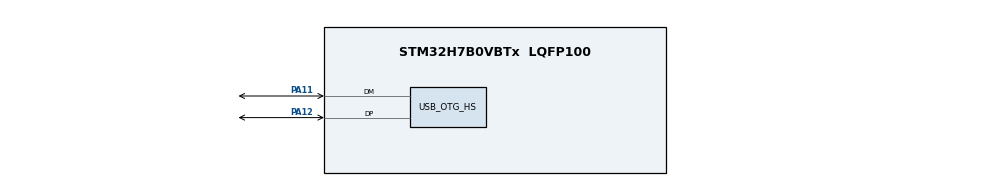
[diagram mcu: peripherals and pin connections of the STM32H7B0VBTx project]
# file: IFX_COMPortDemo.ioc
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Mcu.Family=STM32H7
Mcu.Name=STM32H7B0VBTx
Mcu.Package=LQFP100
NVIC.OTG_HS_EP1_IN_IRQn=true\:0\:0\:false\:false\:true\:true\:true\:true
NVIC.OTG_HS_EP1_OUT_IRQn=true\:0\:0\:false\:false\:true\:true\:true\:true
NVIC.OTG_HS_IRQn=true\:0\:0\:false\:false\:true\:true\:true\:true
NVIC.PriorityGroup=NVIC_PRIORITYGROUP_4
PA11.Mode=Device_Only_FS
PA11.Signal=USB_OTG_HS_DM
PA12.Mode=Device_Only_FS
PA12.Signal=USB_OTG_HS_DP
PA13.Mode=Trace_Asynchronous_SW
PA13.Signal=DEBUG_JTMS-SWDIO
PA14.Mode=Trace_Asynchronous_SW
PA14.Signal=DEBUG_JTCK-SWCLK
PB3.Mode=Trace_Asynchronous_SW
PB3.Signal=DEBUG_JTDO-SWO
PH0-OSC_IN.Mode=HSE-External-Oscillator
PH0-OSC_IN.Signal=RCC_OSC_IN
PH1-OSC_OUT.Mode=HSE-External-Oscillator
PH1-OSC_OUT.Signal=RCC_OSC_OUT
ProjectManager.HeapSize=0x200
ProjectManager.StackSize=0x400
ProjectManager.TargetToolchain=STM32CubeIDE
RCC.ADCFreq_Value=50390625
RCC.APB1Freq_Value=140000000
RCC.APB2Freq_Value=140000000
RCC.APB3Freq_Value=140000000
RCC.APB4Freq_Value=140000000
RCC.CDPPRE=RCC_APB3_DIV2
RCC.CDPPRE1=RCC_APB1_DIV2
RCC.CDPPRE2=RCC_APB2_DIV2
RCC.CortexFreq_Value=280000000
RCC.DIVM1=5
RCC.DIVM3=25
RCC.DIVN1=112
RCC.DIVN3=192
RCC.DIVQ3=4
RCC.HCLKFreq_Value=280000000
RCC.HSE_VALUE=25000000
RCC.PLL2FRACN=0
RCC.PLL3FRACN=0
RCC.PLLFRACN=0
RCC.PLLSourceVirtual=RCC_PLLSOURCE_HSE
RCC.SRDPPRE=RCC_APB4_DIV2
RCC.SYSCLKFreq_VALUE=280000000
RCC.SYSCLKSource=RCC_SYSCLKSOURCE_PLLCLK
RCC.USBCLockSelection=RCC_USBCLKSOURCE_PLL3
RCC.USBFreq_Value=48000000
USB_DEVICE.CLASS_NAME_HS=CDC
USB_DEVICE.VirtualMode=Cdc
USB_DEVICE.VirtualModeHS=Cdc_HS
USB_OTG_HS.VirtualMode-Device_Only_FS=Device_Only_FS
USB_OTG_HS.dma_enable-Device_Only_FS=DISABLE
VP_USB_DEVICE_VS_USB_DEVICE_CDC_HS.Mode=CDC_HS
board=custom

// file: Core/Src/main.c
/* USER CODE BEGIN Header */
/**
  ******************************************************************************
  * @file           : main.c
  * @brief          : Main program body
  ******************************************************************************
  * @attention
  *
  * Copyright (c) 2025 STMicroelectronics.
  * All rights reserved.
  *
  * This software is licensed under terms that can be found in the LICENSE file
  * in the root directory of this software component.
  * If no LICENSE file comes with this software, it is provided AS-IS.
  *
  ******************************************************************************
  */
/* USER CODE END Header */
#include "main.h"
#include "usb_device.h"

/* USER CODE BEGIN Includes */
#include "usbd_cdc_if.h"
/* USER CODE END Includes */

/* USER CODE BEGIN PD */
#define USBBUF_MAXLEN 128
/* USER CODE END PD */

void SystemClock_Config(void);
static void MX_GPIO_Init(void);

/* USER CODE BEGIN 0 */
uint8_t usbTxBuf[USBBUF_MAXLEN];
uint8_t usbRxBuf[USBBUF_MAXLEN];

uint16_t usbTxBufLen = 0;
uint16_t usbRxBufLen = 0;

uint8_t  usbRxFlag 	 = 0;

void USB_RXCallback(uint8_t* Buf, uint32_t *Len) {

	memcpy(usbRxBuf, Buf, *Len);
	usbRxBufLen = *Len;
	usbRxFlag = 1;

}

/* USER CODE END 0 */

int main(void)
{

  /* MCU Configuration--------------------------------------------------------*/

  /* Reset of all peripherals, Initializes the Flash interface and the Systick. */
  HAL_Init();

  /* Configure the system clock */
  SystemClock_Config();

  /* Initialize all configured peripherals */
  MX_GPIO_Init();
  MX_USB_DEVICE_Init();

  /* Infinite loop */
  while (1)
  {

    /* USER CODE BEGIN 3 */
	  if (usbRxFlag && usbRxBufLen) {

		  uint32_t timeNowMS = HAL_GetTick();

		  usbTxBufLen = snprintf((char *) usbTxBuf, USBBUF_MAXLEN, "[%02lu:%02lu] %u\r\n", (timeNowMS / 60000), (timeNowMS / 1000) % 60, usbRxBufLen);

		  CDC_Transmit_HS(usbTxBuf, usbTxBufLen);

		  usbRxFlag = 0;
		  usbRxBufLen = 0;

	  }

  }
  /* USER CODE END 3 */
}

void SystemClock_Config(void)
{
  RCC_OscInitTypeDef RCC_OscInitStruct = {0};
  RCC_ClkInitTypeDef RCC_ClkInitStruct = {0};

  /*AXI clock gating */
  RCC->CKGAENR = 0xFFFFFFFF;

  /** Supply configuration update enable
  */
  HAL_PWREx_ConfigSupply(PWR_LDO_SUPPLY);

  /** Configure the main internal regulator output voltage
  */
  __HAL_PWR_VOLTAGESCALING_CONFIG(PWR_REGULATOR_VOLTAGE_SCALE0);

  while(!__HAL_PWR_GET_FLAG(PWR_FLAG_VOSRDY)) {}

  /** Initializes the RCC Oscillators according to the specified parameters
  * in the RCC_OscInitTypeDef structure.
  */
  RCC_OscInitStruct.OscillatorType = RCC_OSCILLATORTYPE_HSE;
  RCC_OscInitStruct.HSEState = RCC_HSE_ON;
  RCC_OscInitStruct.PLL.PLLState = RCC_PLL_ON;
  RCC_OscInitStruct.PLL.PLLSource = RCC_PLLSOURCE_HSE;
  RCC_OscInitStruct.PLL.PLLM = 5;
  RCC_OscInitStruct.PLL.PLLN = 112;
  RCC_OscInitStruct.PLL.PLLP = 2;
  RCC_OscInitStruct.PLL.PLLQ = 2;
  RCC_OscInitStruct.PLL.PLLR = 2;
  RCC_OscInitStruct.PLL.PLLRGE = RCC_PLL1VCIRANGE_2;
  RCC_OscInitStruct.PLL.PLLVCOSEL = RCC_PLL1VCOWIDE;
  RCC_OscInitStruct.PLL.PLLFRACN = 0;
  if (HAL_RCC_OscConfig(&RCC_OscInitStruct) != HAL_OK)
  {
    Error_Handler();
  }

  /** Initializes the CPU, AHB and APB buses clocks
  */
  RCC_ClkInitStruct.ClockType = RCC_CLOCKTYPE_HCLK|RCC_CLOCKTYPE_SYSCLK
                              |RCC_CLOCKTYPE_PCLK1|RCC_CLOCKTYPE_PCLK2
                              |RCC_CLOCKTYPE_D3PCLK1|RCC_CLOCKTYPE_D1PCLK1;
  RCC_ClkInitStruct.SYSCLKSource = RCC_SYSCLKSOURCE_PLLCLK;
  RCC_ClkInitStruct.SYSCLKDivider = RCC_SYSCLK_DIV1;
  RCC_ClkInitStruct.AHBCLKDivider = RCC_HCLK_DIV1;
  RCC_ClkInitStruct.APB3CLKDivider = RCC_APB3_DIV2;
  RCC_ClkInitStruct.APB1CLKDivider = RCC_APB1_DIV2;
  RCC_ClkInitStruct.APB2CLKDivider = RCC_APB2_DIV2;
  RCC_ClkInitStruct.APB4CLKDivider = RCC_APB4_DIV2;

  if (HAL_RCC_ClockConfig(&RCC_ClkInitStruct, FLASH_LATENCY_6) != HAL_OK)
  {
    Error_Handler();
  }
}

static void MX_GPIO_Init(void)
{

  /* GPIO Ports Clock Enable */
  __HAL_RCC_GPIOH_CLK_ENABLE();
  __HAL_RCC_GPIOA_CLK_ENABLE();
  __HAL_RCC_GPIOB_CLK_ENABLE();

}

void Error_Handler(void)
{
  __disable_irq();
  while (1)
  {
  }
}
